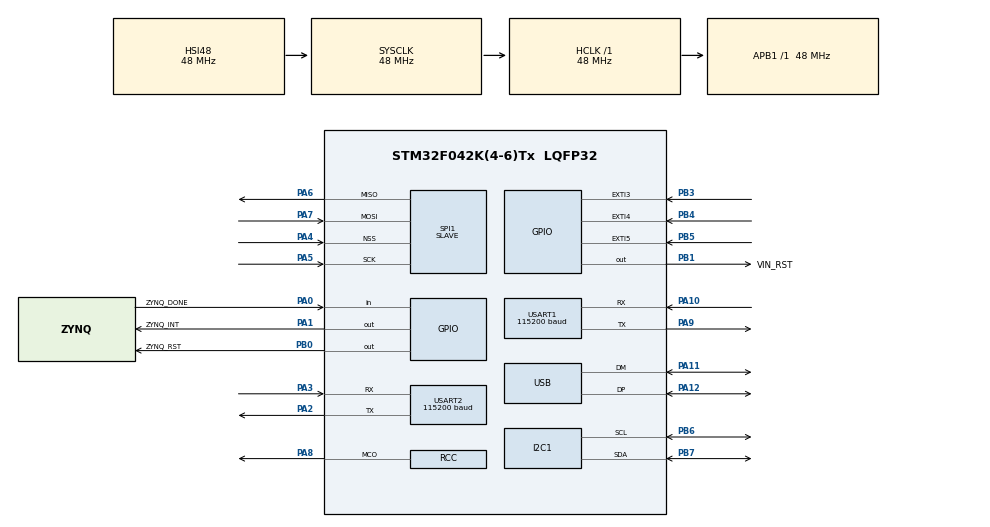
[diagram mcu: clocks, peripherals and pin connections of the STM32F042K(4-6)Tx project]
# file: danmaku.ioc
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Mcu.Family=STM32F0
Mcu.Name=STM32F042K(4-6)Tx
Mcu.Package=LQFP32
NVIC.USB_IRQn=true\:0\:0\:false\:false\:true\:true\:true
PA0.GPIO_Label=ZYNQ_DONE
PA0.GPIO_PuPd=GPIO_PULLDOWN
PA0.Signal=GPIO_Input
PA1.GPIO_Label=ZYNQ_INT
PA1.Signal=GPIO_Output
PA10.Mode=Asynchronous
PA10.Signal=USART1_RX
PA11.Mode=Device
PA11.Signal=USB_DM
PA12.Mode=Device
PA12.Signal=USB_DP
PA13.Mode=Serial_Wire
PA13.Signal=SYS_SWDIO
PA14.Mode=Serial_Wire
PA14.Signal=SYS_SWCLK
PA2.Mode=Asynchronous
PA2.Signal=USART2_TX
PA3.Mode=Asynchronous
PA3.Signal=USART2_RX
PA4.Mode=NSS_Signal_Hard_Input
PA4.Signal=SPI1_NSS
PA5.Mode=Full_Duplex_Slave
PA5.Signal=SPI1_SCK
PA6.Mode=Full_Duplex_Slave
PA6.Signal=SPI1_MISO
PA7.Mode=Full_Duplex_Slave
PA7.Signal=SPI1_MOSI
PA8.Mode=Clock-out
PA8.Signal=RCC_MCO
PA9.Mode=Asynchronous
PA9.Signal=USART1_TX
PB0.GPIO_Label=ZYNQ_RST
PB0.GPIO_ModeDefaultOutputPP=GPIO_MODE_OUTPUT_OD
PB0.GPIO_PuPd=GPIO_PULLUP
PB0.PinState=GPIO_PIN_SET
PB0.Signal=GPIO_Output
PB1.GPIO_Label=VIN_RST
PB1.Signal=GPIO_Output
PB3.Signal=GPXTI3
PB4.Signal=GPXTI4
PB5.Signal=GPXTI5
PB6.Mode=I2C
PB6.Signal=I2C1_SCL
PB7.Mode=I2C
PB7.Signal=I2C1_SDA
ProjectManager.HeapSize=0x200
ProjectManager.StackSize=0x400
ProjectManager.TargetToolchain=Makefile
RCC.AHBFreq_Value=48000000
RCC.APB1Freq_Value=48000000
RCC.APB1TimFreq_Value=48000000
RCC.HCLKFreq_Value=48000000
RCC.RCC_MCODiv=RCC_MCODIV_4
RCC.SYSCLKFreq_VALUE=48000000
RCC.SYSCLKSource=RCC_SYSCLKSOURCE_HSI48
SPI1.DataSize=SPI_DATASIZE_8BIT
SPI1.Direction=SPI_DIRECTION_2LINES
SPI1.Mode=SPI_MODE_SLAVE
SPI1.VirtualNSS=VM_NSSHARD
SPI1.VirtualType=VM_SLAVE
USART1.BaudRate=115200
USART1.VirtualMode-Asynchronous=VM_ASYNC
USART1.WordLength=WORDLENGTH_8B
USART2.BaudRate=115200
USART2.VirtualMode-Asynchronous=VM_ASYNC
USART2.WordLength=WORDLENGTH_8B
USB_DEVICE.CLASS_NAME_FS=CDC
USB_DEVICE.USBD_HandleTypeDef=hUsbDeviceFS
USB_DEVICE.VirtualMode=Cdc
USB_DEVICE.VirtualModeFS=Cdc_FS
VP_USB_DEVICE_VS_USB_DEVICE_CDC_FS.Mode=CDC_FS
board=danmaku

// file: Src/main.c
/* USER CODE BEGIN Header */
/**
  ******************************************************************************
  * @file           : main.c
  * @brief          : Main program body
  ******************************************************************************
  * @attention
  *
  * <h2><center>&copy; Copyright (c) 2019 STMicroelectronics.
  * All rights reserved.</center></h2>
  *
  * This software component is licensed by ST under Ultimate Liberty license
  * SLA0044, the "License"; You may not use this file except in compliance with
  * the License. You may obtain a copy of the License at:
  *                             www.st.com/SLA0044
  *
  ******************************************************************************
  */
/* USER CODE END Header */

#include "main.h"
#include "usb_device.h"

/* USER CODE BEGIN Includes */
#include "common.h"
#include "system_manage.h"
#include "hdmi_dec_enc.h"
/* USER CODE END Includes */

I2C_HandleTypeDef hi2c1;

SPI_HandleTypeDef hspi1;

UART_HandleTypeDef huart1;
UART_HandleTypeDef huart2;

/* USER CODE BEGIN PV */
/* Private variables ---------------------------------------------------------*/

/* USER CODE END PV */

void SystemClock_Config(void);
static void MX_GPIO_Init(void);
static void MX_I2C1_Init(void);
static void MX_SPI1_Init(void);
static void MX_USART1_UART_Init(void);
static void MX_USART2_UART_Init(void);
/* USER CODE BEGIN PFP */
/* Private function prototypes -----------------------------------------------*/

/* Retargeting functions for gcc-arm-embedded */

int _write (int fd, char *ptr, int len)
{
  /* Write "len" of char from "ptr" to file id "fd"
   * Return number of char written.
   * Need implementing with UART here. */
  HAL_UART_Transmit(&huart2, (uint8_t*)ptr, len, 1000);
  return len;
}
/* USER CODE END PFP */

int main(void)
{

  /* MCU Configuration--------------------------------------------------------*/

  /* Reset of all peripherals, Initializes the Flash interface and the Systick. */
  HAL_Init();

  /* Configure the system clock */
  SystemClock_Config();

  /* Initialize all configured peripherals */
  MX_GPIO_Init();
  MX_I2C1_Init();
  MX_SPI1_Init();
  MX_USART1_UART_Init();
  MX_USART2_UART_Init();
  MX_USB_DEVICE_Init();
  /* USER CODE BEGIN 2 */
  INFO_MSG("Danmaku9 SMC starting...");
  HDMI_Init();
  /* USER CODE END 2 */

  /* Infinite loop */
  while (1)
  {

    /* USER CODE BEGIN 3 */
    HDMI_Task();
    SystemManage_Task();

  }
  /* USER CODE END 3 */
}

void SystemClock_Config(void)
{
  RCC_OscInitTypeDef RCC_OscInitStruct = {0};
  RCC_ClkInitTypeDef RCC_ClkInitStruct = {0};
  RCC_PeriphCLKInitTypeDef PeriphClkInit = {0};

  /** Initializes the CPU, AHB and APB busses clocks
  */
  RCC_OscInitStruct.OscillatorType = RCC_OSCILLATORTYPE_HSI|RCC_OSCILLATORTYPE_HSI48;
  RCC_OscInitStruct.HSIState = RCC_HSI_ON;
  RCC_OscInitStruct.HSI48State = RCC_HSI48_ON;
  RCC_OscInitStruct.HSICalibrationValue = RCC_HSICALIBRATION_DEFAULT;
  RCC_OscInitStruct.PLL.PLLState = RCC_PLL_NONE;
  if (HAL_RCC_OscConfig(&RCC_OscInitStruct) != HAL_OK)
  {
    Error_Handler();
  }
  /** Initializes the CPU, AHB and APB busses clocks
  */
  RCC_ClkInitStruct.ClockType = RCC_CLOCKTYPE_HCLK|RCC_CLOCKTYPE_SYSCLK
                              |RCC_CLOCKTYPE_PCLK1;
  RCC_ClkInitStruct.SYSCLKSource = RCC_SYSCLKSOURCE_HSI48;
  RCC_ClkInitStruct.AHBCLKDivider = RCC_SYSCLK_DIV1;
  RCC_ClkInitStruct.APB1CLKDivider = RCC_HCLK_DIV1;

  if (HAL_RCC_ClockConfig(&RCC_ClkInitStruct, FLASH_LATENCY_1) != HAL_OK)
  {
    Error_Handler();
  }
  PeriphClkInit.PeriphClockSelection = RCC_PERIPHCLK_USB|RCC_PERIPHCLK_USART1
                              |RCC_PERIPHCLK_I2C1;
  PeriphClkInit.Usart1ClockSelection = RCC_USART1CLKSOURCE_PCLK1;
  PeriphClkInit.I2c1ClockSelection = RCC_I2C1CLKSOURCE_HSI;
  PeriphClkInit.UsbClockSelection = RCC_USBCLKSOURCE_HSI48;

  if (HAL_RCCEx_PeriphCLKConfig(&PeriphClkInit) != HAL_OK)
  {
    Error_Handler();
  }
  HAL_RCC_MCOConfig(RCC_MCO, RCC_MCO1SOURCE_SYSCLK, RCC_MCODIV_4);
}

static void MX_I2C1_Init(void)
{

  hi2c1.Instance = I2C1;
  hi2c1.Init.Timing = 0x2000090E;
  hi2c1.Init.OwnAddress1 = 0;
  hi2c1.Init.AddressingMode = I2C_ADDRESSINGMODE_7BIT;
  hi2c1.Init.DualAddressMode = I2C_DUALADDRESS_DISABLE;
  hi2c1.Init.OwnAddress2 = 0;
  hi2c1.Init.OwnAddress2Masks = I2C_OA2_NOMASK;
  hi2c1.Init.GeneralCallMode = I2C_GENERALCALL_DISABLE;
  hi2c1.Init.NoStretchMode = I2C_NOSTRETCH_DISABLE;
  if (HAL_I2C_Init(&hi2c1) != HAL_OK)
  {
    Error_Handler();
  }
  /** Configure Analogue filter
  */
  if (HAL_I2CEx_ConfigAnalogFilter(&hi2c1, I2C_ANALOGFILTER_ENABLE) != HAL_OK)
  {
    Error_Handler();
  }
  /** Configure Digital filter
  */
  if (HAL_I2CEx_ConfigDigitalFilter(&hi2c1, 0) != HAL_OK)
  {
    Error_Handler();
  }

}

static void MX_SPI1_Init(void)
{

  /* SPI1 parameter configuration*/
  hspi1.Instance = SPI1;
  hspi1.Init.Mode = SPI_MODE_SLAVE;
  hspi1.Init.Direction = SPI_DIRECTION_2LINES;
  hspi1.Init.DataSize = SPI_DATASIZE_8BIT;
  hspi1.Init.CLKPolarity = SPI_POLARITY_LOW;
  hspi1.Init.CLKPhase = SPI_PHASE_1EDGE;
  hspi1.Init.NSS = SPI_NSS_HARD_INPUT;
  hspi1.Init.FirstBit = SPI_FIRSTBIT_MSB;
  hspi1.Init.TIMode = SPI_TIMODE_DISABLE;
  hspi1.Init.CRCCalculation = SPI_CRCCALCULATION_DISABLE;
  hspi1.Init.CRCPolynomial = 7;
  hspi1.Init.CRCLength = SPI_CRC_LENGTH_DATASIZE;
  hspi1.Init.NSSPMode = SPI_NSS_PULSE_DISABLE;
  if (HAL_SPI_Init(&hspi1) != HAL_OK)
  {
    Error_Handler();
  }

}

static void MX_USART1_UART_Init(void)
{

  huart1.Instance = USART1;
  huart1.Init.BaudRate = 115200;
  huart1.Init.WordLength = UART_WORDLENGTH_8B;
  huart1.Init.StopBits = UART_STOPBITS_1;
  huart1.Init.Parity = UART_PARITY_NONE;
  huart1.Init.Mode = UART_MODE_TX_RX;
  huart1.Init.HwFlowCtl = UART_HWCONTROL_NONE;
  huart1.Init.OverSampling = UART_OVERSAMPLING_16;
  huart1.Init.OneBitSampling = UART_ONE_BIT_SAMPLE_DISABLE;
  huart1.AdvancedInit.AdvFeatureInit = UART_ADVFEATURE_NO_INIT;
  if (HAL_UART_Init(&huart1) != HAL_OK)
  {
    Error_Handler();
  }

}

static void MX_USART2_UART_Init(void)
{

  huart2.Instance = USART2;
  huart2.Init.BaudRate = 115200;
  huart2.Init.WordLength = UART_WORDLENGTH_8B;
  huart2.Init.StopBits = UART_STOPBITS_1;
  huart2.Init.Parity = UART_PARITY_NONE;
  huart2.Init.Mode = UART_MODE_TX_RX;
  huart2.Init.HwFlowCtl = UART_HWCONTROL_NONE;
  huart2.Init.OverSampling = UART_OVERSAMPLING_16;
  huart2.Init.OneBitSampling = UART_ONE_BIT_SAMPLE_DISABLE;
  huart2.AdvancedInit.AdvFeatureInit = UART_ADVFEATURE_NO_INIT;
  if (HAL_UART_Init(&huart2) != HAL_OK)
  {
    Error_Handler();
  }

}

static void MX_GPIO_Init(void)
{
  GPIO_InitTypeDef GPIO_InitStruct = {0};

  /* GPIO Ports Clock Enable */
  __HAL_RCC_GPIOA_CLK_ENABLE();
  __HAL_RCC_GPIOB_CLK_ENABLE();

  /*Configure GPIO pin Output Level */
  HAL_GPIO_WritePin(ZYNQ_INT_GPIO_Port, ZYNQ_INT_Pin, GPIO_PIN_RESET);

  /*Configure GPIO pin Output Level */
  HAL_GPIO_WritePin(ZYNQ_RST_GPIO_Port, ZYNQ_RST_Pin, GPIO_PIN_SET);

  /*Configure GPIO pin Output Level */
  HAL_GPIO_WritePin(VIN_RST_GPIO_Port, VIN_RST_Pin, GPIO_PIN_RESET);

  /*Configure GPIO pin : ZYNQ_DONE_Pin */
  GPIO_InitStruct.Pin = ZYNQ_DONE_Pin;
  GPIO_InitStruct.Mode = GPIO_MODE_INPUT;
  GPIO_InitStruct.Pull = GPIO_PULLDOWN;
  HAL_GPIO_Init(ZYNQ_DONE_GPIO_Port, &GPIO_InitStruct);

  /*Configure GPIO pin : ZYNQ_INT_Pin */
  GPIO_InitStruct.Pin = ZYNQ_INT_Pin;
  GPIO_InitStruct.Mode = GPIO_MODE_OUTPUT_PP;
  GPIO_InitStruct.Pull = GPIO_NOPULL;
  GPIO_InitStruct.Speed = GPIO_SPEED_FREQ_LOW;
  HAL_GPIO_Init(ZYNQ_INT_GPIO_Port, &GPIO_InitStruct);

  /*Configure GPIO pin : ZYNQ_RST_Pin */
  GPIO_InitStruct.Pin = ZYNQ_RST_Pin;
  GPIO_InitStruct.Mode = GPIO_MODE_OUTPUT_OD;
  GPIO_InitStruct.Pull = GPIO_PULLUP;
  GPIO_InitStruct.Speed = GPIO_SPEED_FREQ_LOW;
  HAL_GPIO_Init(ZYNQ_RST_GPIO_Port, &GPIO_InitStruct);

  /*Configure GPIO pin : VIN_RST_Pin */
  GPIO_InitStruct.Pin = VIN_RST_Pin;
  GPIO_InitStruct.Mode = GPIO_MODE_OUTPUT_PP;
  GPIO_InitStruct.Pull = GPIO_NOPULL;
  GPIO_InitStruct.Speed = GPIO_SPEED_FREQ_LOW;
  HAL_GPIO_Init(VIN_RST_GPIO_Port, &GPIO_InitStruct);

  /*Configure GPIO pin : PA8 */
  GPIO_InitStruct.Pin = GPIO_PIN_8;
  GPIO_InitStruct.Mode = GPIO_MODE_AF_PP;
  GPIO_InitStruct.Pull = GPIO_NOPULL;
  GPIO_InitStruct.Speed = GPIO_SPEED_FREQ_LOW;
  GPIO_InitStruct.Alternate = GPIO_AF0_MCO;
  HAL_GPIO_Init(GPIOA, &GPIO_InitStruct);

  /*Configure GPIO pins : PB3 PB4 PB5 */
  GPIO_InitStruct.Pin = GPIO_PIN_3|GPIO_PIN_4|GPIO_PIN_5;
  GPIO_InitStruct.Mode = GPIO_MODE_IT_RISING;
  GPIO_InitStruct.Pull = GPIO_NOPULL;
  HAL_GPIO_Init(GPIOB, &GPIO_InitStruct);

}

void Error_Handler(void)
{
}

/************************ (C) COPYRIGHT STMicroelectronics *****END OF FILE****/
